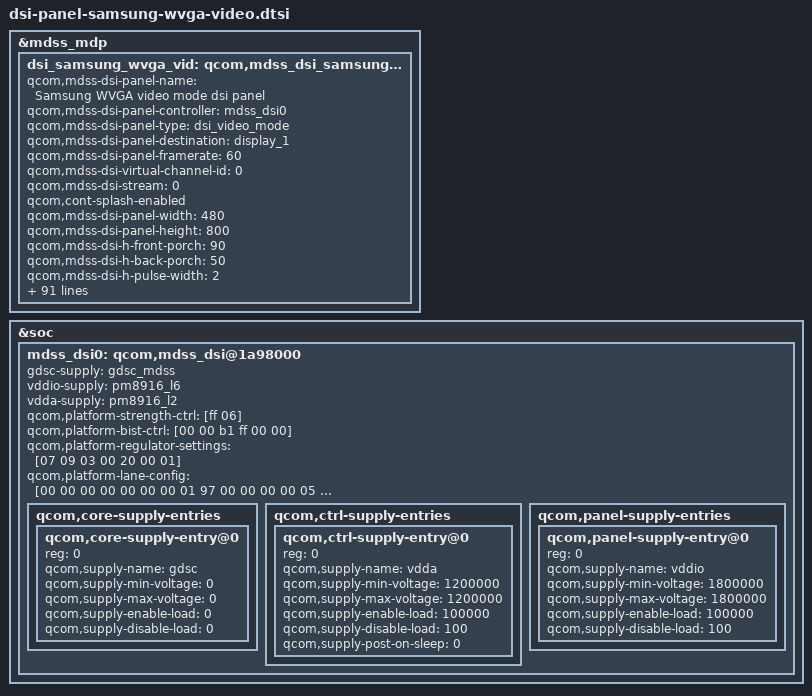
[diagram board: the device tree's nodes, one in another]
/* Copyright (c) 2013-2014, The Linux Foundation. All rights reserved.
 *
 * This program is free software; you can redistribute it and/or modify
 * it under the terms of the GNU General Public License version 2 and
 * only version 2 as published by the Free Software Foundation.
 *
 * This program is distributed in the hope that it will be useful,
 * but WITHOUT ANY WARRANTY; without even the implied warranty of
 * MERCHANTABILITY or FITNESS FOR A PARTICULAR PURPOSE.  See the
 * GNU General Public License for more details.
 */

/*---------------------------------------------------------------------------
 * This file is autogenerated file using gcdb parser. Please do not edit it.
 * Update input XML file to add a new entry or update variable in this file
 * VERSION = "1.0"
 *---------------------------------------------------------------------------

 */
&mdss_mdp {
	dsi_samsung_wvga_vid: qcom,mdss_dsi_samsung_wvga_video {
		qcom,mdss-dsi-panel-name = "Samsung WVGA video mode dsi panel";
		qcom,mdss-dsi-panel-controller = <&mdss_dsi0>;
		qcom,mdss-dsi-panel-type = "dsi_video_mode";
		qcom,mdss-dsi-panel-destination = "display_1";
		qcom,mdss-dsi-panel-framerate = <60>;
		qcom,mdss-dsi-virtual-channel-id = <0>;
		qcom,mdss-dsi-stream = <0>;
		qcom,cont-splash-enabled;
		qcom,mdss-dsi-panel-width = <480>;
		qcom,mdss-dsi-panel-height = <800>;
		qcom,mdss-dsi-h-front-porch = <90>;
		qcom,mdss-dsi-h-back-porch = <50>;
		qcom,mdss-dsi-h-pulse-width = <2>;
		qcom,mdss-dsi-h-sync-skew = <0>;
		qcom,mdss-dsi-v-back-porch = <2>;
		qcom,mdss-dsi-v-front-porch = <13>;
		qcom,mdss-dsi-v-pulse-width = <1>;
		qcom,mdss-dsi-h-left-border = <0>;
		qcom,mdss-dsi-h-right-border = <0>;
		qcom,mdss-dsi-v-top-border = <0>;
		qcom,mdss-dsi-v-bottom-border = <0>;
		qcom,mdss-dsi-bpp = <24>;
		qcom,mdss-dsi-underflow-color = <0xff>;
		qcom,mdss-dsi-border-color = <0>;
		qcom,mdss-dsi-on-command = [
			39 01 00 00 00 00 03 f0 5a 5a /* Tesk key ON */
			39 01 00 00 00 00 03 fc 5a 5a
			05 01 00 00 78 00 02 11 00 /* Sleep out  wait 120ms */

			/* Common setting - AVDD Setting */
			39 01 00 00 00 00 04 b8 38 0b 30

			/* Brightness condition set */
			39 01 00 00 00 00 22 /* Brightness gamma */
				ca 01 00 01 00 01 00 /* V255 RGB*/
				80 80 80 /* V203 RGB*/
				80 80 80 /* V151 RGB*/
				80 80 80 /* V87 RGB*/
				80 80 80 /* V51 RGB*/
				80 80 80 /* V35 RGB*/
				80 80 80 /* V23 RGB*/
				80 80 80 /* V11 RGB*/
				80 80 80 /* V3 RGB*/
				00 00 00 /* VT RGB*/

			39 01 00 00 00 00 06 b2 40 08 20 00 08 /* AID set */

			/* ELVSS Condition set */
			39 01 00 00 00 00 03 b6 28 0b /* ELVSS */

			/* ETC */
			39 01 00 00 00 00 02 55 00 /* ACL set */
			39 01 00 00 00 00 03 fc a5 a5
			05 01 00 00 00 00 02 29 00 /* Display on */];
		qcom,mdss-dsi-off-command = [05 01 00 00 23 00 02 28 00
				 05 01 00 00 78 00 02 10 00];
		qcom,mdss-dsi-gamma-update = [39 01 00 00 00 00 02 F7 03];
		qcom,mdss-dsi-on-command-state = "dsi_lp_mode";
		qcom,mdss-dsi-off-command-state = "dsi_hs_mode";
		qcom,mdss-dsi-h-sync-pulse = <0>;
		qcom,mdss-dsi-traffic-mode = "burst_mode";
		qcom,mdss-dsi-bllp-eof-power-mode;
		qcom,mdss-dsi-bllp-power-mode;
		qcom,mdss-dsi-lane-0-state;
		qcom,mdss-dsi-lane-1-state;
		qcom,mdss-dsi-panel-timings = [5E 16 0E 00 38 3C 12 1A 1C 03 04 00];
		qcom,mdss-dsi-t-clk-post = <0x04>;
		qcom,mdss-dsi-t-clk-pre = <0x17>;
		qcom,mdss-dsi-bl-min-level = <1>;
		qcom,mdss-dsi-bl-max-level = <255>;
		qcom,mdss-dsi-dma-trigger = "trigger_sw";
		qcom,mdss-dsi-mdp-trigger = "none";
		qcom,mdss-force-clk-lane-hs = <1>;
		qcom,mdss-dsi-bl-pmic-control-type = "bl_ctrl_dcs";
		qcom,mdss-dsi-reset-sequence = <1 5>, <0 1>, <1 10>;
		qcom,mdss-pan-physical-width-dimension = <56>;
		qcom,mdss-pan-physical-height-dimension = <94>;
		qcom,mdss-dsi-lp11-init;
		qcom,mdss-dsi-init-delay-us = <2000>;
		samsung,panel-manufacture-id-read-cmds = [
			06 01 00 00 00 00 01 DA 01 00
			06 01 00 00 00 00 01 DB 01 00
			06 01 00 00 00 00 01 DC 01 00
		];
		samsung,panel-acl-off-cmds = [39 01 00 00 72 00 02 55 00];
		/*
		the last byte in read commands  represent READ LENGH,
		like below  READ LENGH = 0x21
		*/

		samsung,panel-nv-mtp-read-cmds = [ 06 01 00 00 00 00 01 C8 21 00];
		samsung,panel-nv-mtp-read-hbm-cmds = [ 06 01 00 00 00 00 01 B5 07 0C];	/* read B5 13~19th , 12=0x0C*/
		samsung,panel-nv-mtp-read-hbm2-cmds = [ 06 01 00 00 00 00 01 B5 03 19];	/* read B5 26~28th , 25=0x19*/
		samsung,panel-nv-mtp-read-hbm3-cmds = [ 06 01 00 00 00 00 01 B6 11 00];	/* read B6 03~17th , 03=0x03*/
		samsung,panel-nv-mdnie-read-cmds = [ 06 01 00 00 00 00 01 B5 04 13];
		samsung,panel-test-key-enable-cmds = [ 39 00 00 00 00 00 03 F0 5A 5A];
		samsung,panel-test-key-disable-cmds = [ 39 01 00 00 00 00 03 F0 A5 A5];
		samsung,panel-nv-mdate-read-cmds = [ 06 01 00 00 00 00 01 B5 02 17];	/* read B6 24~25th , 23=0x17*/

		samsung,panel-nv-read-enable-cmds = [39 01 00 00 00 00 03 F0 5A 5A
						39 01 00 00 00 00 03 FC 5A 5A];
		samsung,panel-nv-read-disable-cmds = [39 01 00 00 00 00 03 FC A5 A5
						39 01 00 00 00 00 03 F0 A5 A5];
		samsung,panel-gamma-hbm-cmds-list = [39 00 00 00 00 00 22            /* Brightness Condition Set - Gamma 2.2 Setting*/
						ca 01 00 01 00 01 00 80
						80 80 80 80 80 80 80 80
						80 80 80 80 80 80 80 80
						80 80 80 80 80 80 80 00
						00 00
			];
		samsung,panel-etc-hbm-cmds = [
					39 00 00 00 00 00 06 B2 00 00 00 00 06	/* samsung_brightness_aor_condition */
					39 00 00 00 00 00 12 B6 28 0B 7C 7D 7C 7A 79 7A 7E 7E		/* C8h 40th - MPS / ELVSS setting */
						7E 7F 7E 7C 00 00 1A
					39 00 00 00 00 00 02 55 02		/* power saving Set */
					39 00 00 00 00 00 02 F7 03		/* Gamma, LTPS(AID) update */
			];
		samsung,panel-hbm-off-cmds = [
					39 00 00 00 00 00 12 B6 28 0B 7C 7D 7C 7A 79 7A 7E 7E		/* C8h 40th - MPS / ELVSS setting */
						7E 7F 7E 7C 00 00 1A
					39 01 00 00 00 00 02 F7 03		/* Gamma, LTPS(AID) update */
		];
		/*
		* ************************************************************************************************************************
		* AID command list and mappings
		* ************************************************************************************************************************
		*/
		samsung,panel-aid-cmds-list-350 = [
			39 00 00 00 00 00 06 B2 40 08 20 03 11 /* 0 samsung_brightness_aor_0p4 */
			39 00 00 00 00 00 06 B2 40 08 20 03 07 /* 1 samsung_brightness_aor_40p0 */
			39 00 00 00 00 00 06 B2 40 08 20 03 02 /* 2 samsung_brightness_aor_0p4 181*/
			39 00 00 00 00 00 06 B2 40 08 20 02 F7 /* 3 samsung_brightness_aor_0p4 179*/
			39 00 00 00 00 00 06 B2 40 08 20 02 F4 /* 4 samsung_brightness_aor_0p4 177*/
			39 00 00 00 00 00 06 B2 40 08 20 02 E8 /* 5 samsung_brightness_aor_0p4 175*/
			39 00 00 00 00 00 06 B2 40 08 20 02 E4 /* 6 samsung_brightness_aor_0p4 173*/
			39 00 00 00 00 00 06 B2 40 08 20 02 E2 /* 7 samsung_brightness_aor_0p4 110*/
			39 00 00 00 00 00 06 B2 40 08 20 02 D7 /* 8 samsung_brightness_aor_0p4 109*/
			39 00 00 00 00 00 06 B2 40 08 20 02 D2 /* 9 samsung_brightness_aor_0p4 108*/
			39 00 00 00 00 00 06 B2 40 08 20 02 C6 /* 10 samsung_brightness_aor_0p4 */
			39 00 00 00 00 00 06 B2 40 08 20 02 C4 /* 11 samsung_brightness_aor_0p4 108*/
			39 00 00 00 00 00 06 B2 40 08 20 02 B8 /* 12 samsung_brightness_aor_0p4 */
			39 00 00 00 00 00 06 B2 40 08 20 02 B3 /* 13 samsung_brightness_aor_0p4 */
			39 00 00 00 00 00 06 B2 40 08 20 02 A7 /* 14 samsung_brightness_aor_6p2 */
			39 00 00 00 00 00 06 B2 40 08 20 02 A2 /* 15 samsung_brightness_aor_81p6 */
			39 00 00 00 00 00 06 B2 40 08 20 02 96 /* 16 samsung_brightness_aor_80p6 */
			39 00 00 00 00 00 06 B2 40 08 20 02 89 /* 17 samsung_brightness_aor_79p0 */
			39 00 00 00 00 00 06 B2 40 08 20 02 84 /* 18 samsung_brightness_aor_77p9 */
			39 00 00 00 00 00 06 B2 40 08 20 02 76 /* 19 samsung_brightness_aor_75p8 */
			39 00 00 00 00 00 06 B2 40 08 20 02 67 /* 20samsung_brightness_aor_74p3 */
			39 00 00 00 00 00 06 B2 40 08 20 02 62 /* 21 samsung_brightness_aor_73p2 */
			39 00 00 00 00 00 06 B2 40 08 20 02 54 /* 22 samsung_brightness_aor_71p7 */
			39 00 00 00 00 00 06 B2 40 08 20 02 45 /* 23 samsung_brightness_aor_69p5 */
			39 00 00 00 00 00 06 B2 40 08 20 02 32 /* 24 samsung_brightness_aor_66p9 */
			39 00 00 00 00 00 06 B2 40 08 20 02 23 /* 25 samsung_brightness_aor_64p7 */
			39 00 00 00 00 00 06 B2 40 08 20 02 0C /* 26 samsung_brightness_aor_63p1 */
			39 00 00 00 00 00 06 B2 40 08 20 02 01 /* 27 samsung_brightness_aor_59p9 */
			39 00 00 00 00 00 06 B2 40 08 20 01 E7 /* 28 samsung_brightness_aor_57p3 */
			39 00 00 00 00 00 06 B2 40 08 20 01 D4 /* 29 samsung_brightness_aor_54p6 */
			39 00 00 00 00 00 06 B2 40 08 20 01 BD /* 30 samsung_brightness_aor_51p9 */
			39 00 00 00 00 00 06 B2 40 08 20 02 A6 /* 31 samsung_brightness_aor_48p6 */
			39 00 00 00 00 00 06 B2 40 08 20 01 87 /* 32 samsung_brightness_aor_44p8 */
			39 00 00 00 00 00 06 B2 40 08 20 01 71 /* 33 samsung_brightness_aor_41p0 */
			39 00 00 00 00 00 06 B2 40 08 20 01 49 /* 34 samsung_brightness_aor_37p2 */
			39 00 00 00 00 00 06 B2 40 08 20 01 34 /* 35 samsung_brightness_aor_32p7 */
			39 00 00 00 00 00 06 B2 40 08 20 01 13 /* 36 samsung_brightness_aor_27p7 */
			39 00 00 00 00 00 06 B2 40 08 20 00 E8 /* 37 samsung_brightness_aor_22p8 */
			39 00 00 00 00 00 06 B2 40 08 20 00 C3 /* 38 samsung_brightness_aor_17p7 */
			39 00 00 00 00 00 06 B2 40 08 20 00 97 /* 39 samsung_brightness_aor_11p6 */
			39 00 00 00 00 00 06 B2 40 08 20 00 66 /* 40 samsung_brightness_aor_6p6 */
			39 00 00 00 00 00 06 B2 40 08 20 00 37 /* 41 samsung_brightness_aor_0p5 */
			39 00 00 00 00 00 06 B2 40 08 20 00 08 /* 42 samsung_brightness_aor_40p0 */
			];

		samsung,panel-aid-map-table-350 = <
			5    0         6   1        7    2       8    3      9    4
			10   5         11   6       12   7       13   8     14   9
			15   10        16   11       17   12       19   13     20   14
			21   15        22   16       24   17       25   18     27   19
			29   20        30   21       32   22       34   23     37   24
			39   25        41   26       44   27       47   28     50   29
			53   30        56   31       60   32       64   33     68   34
			72   35        77   35       82   35       87   35     93   35
			98   35        105  35       111  35       119  35     126  35
			134  35        143  35       152  35       162  35     172  36
			183  37        195  38       207  39       220  40     234  41
			249  42        265  42       282  42       300  42     316  42
			333  42        350  42
		>;

		/*
		* ************************************************************************************************************************
		* ACL command list and mappings
		* ************************************************************************************************************************
		*/
		samsung,panel-acl-cmds-list = [
			39 00 00 00 00 00 02 55 00
			39 00 00 00 00 00 02 55 01
			39 00 00 00 00 00 02 55 02
			39 00 00 00 00 00 02 55 03
		];

		samsung,panel-acl-map-table =  <
			5    2         6    2        7    2         8    2      9    2
			10   2         11   2        12   2         13   2      14   2
			15   2         16   2        17   2         19   2      20   2
			21   2         22   2        24   2         25   2      27   2
			29   2         30   2        32   2         34   2      37   2
			39   2         41   2        44   2         47   2      50   2
			53   2         56   2        60   2         64   2      68   2
			72   2         77   2        82   2         87   2      93   2
			98   2         105  2        111  2         119  2      126  2
			134  2         143  2        152  2         162  2      172  2
			183  2         195  2        207  2         220  2      234  2
			249  2         265  2        282  2         300  2      316  2
			333  2         350  2
		>;
		/*
		* ************************************************************************************************************************
		* ELVSS(ACL Off) command list and mappings
		* ************************************************************************************************************************
		*/
		samsung,panel-elvss-cmds-list-350 = [
			39 00 00 00 00 00 03 B6 28 13 /* 0 DEFAULT_ELVSS(0x16) */
			39 00 00 00 00 00 03 B6 28 12 /* 1 DEFAULT_ELVSS(0x15) */
			39 00 00 00 00 00 03 B6 28 11 /* 2 DEFAULT_ELVSS(0x14) */
			39 00 00 00 00 00 03 B6 28 10 /* 3 DEFAULT_ELVSS(0x13) */
			39 00 00 00 00 00 03 B6 28 0F /* 4 DEFAULT_ELVSS(0x12) */
			39 00 00 00 00 00 03 B6 28 0E /* 5 DEFAULT_ELVSS(0x11) */
			39 00 00 00 00 00 03 B6 28 0D /* 6 DEFAULT_ELVSS(0x10) */
			39 00 00 00 00 00 03 B6 28 0C /* 7 DEFAULT_ELVSS(0x0F) */
			39 00 00 00 00 00 03 B6 28 0B /* 8 DEFAULT_ELVSS(0x0E) */
		];
		/* bl_level, Index in elvss command list */
		samsung,panel-elvss-map-table-350 = <
			5    0         6    0        7    0         8    0      9    0
			10   0         11   0        12   0         13   0      14   0
			15   0         16   0        17   0         19   0      20   0
			21   0         22   0        24   0         25   0      27   0
			29   0         30   0        32   0         34   0      37   0
			39   0         41   0        44   0         47   0      50   0
			53   0         56   0        60   0         64   0      68   0
			72   0         77   0        82   0         87   0      93   0
			98   0         105  0        111  0         119  1      126  1
			134  2         143  2        152  3         162  3      172  3
			183  3        195  3       207  4        220  4     234  4
			249  4        265  5       282  5        300   6     316  7
			333  7        350  8
			>;
		samsung,panel-smart-acl-elvss-cmds-list = [
			39 00 00 00 00 00 03 B6 28 15 /* 0 DEFAULT_ELVSS(0x16) */
			39 00 00 00 00 00 03 B6 28 14 /* 1 DEFAULT_ELVSS(0x15) */
			39 00 00 00 00 00 03 B6 28 13 /* 2 DEFAULT_ELVSS(0x14) */
			39 00 00 00 00 00 03 B6 28 12 /* 3 DEFAULT_ELVSS(0x13) */
			39 00 00 00 00 00 03 B6 28 11 /* 4 DEFAULT_ELVSS(0x12) */
			39 00 00 00 00 00 03 B6 28 10 /* 5 DEFAULT_ELVSS(0x11) */
			39 00 00 00 00 00 03 B6 28 0F /* 6 DEFAULT_ELVSS(0x10) */
			39 00 00 00 00 00 03 B6 28 0E /* 7 DEFAULT_ELVSS(0x0F) */
			39 00 00 00 00 00 03 B6 28 0D /* 8 DEFAULT_ELVSS(0x0E) */
		];

			/* bl_level, Index in elvss command list */
		samsung,panel-smart-acl-elvss-map-table = <
			5    0         6    0        7    0         8    0      9    0
			10   0         11   0        12   0         13   0      14   0
			15   0         16   0        17   0         19   0      20   0
			21   0         22   0        24   0         25   0      27   0
			29   0         30   0        32   0         34   0      37   0
			39   0         41   0        44   0         47   0      50   0
			53   0         56   0        60   0         64   0      68   0
			72   0         77   0        82   0         87   0      93   0
			98   0         105  0        111  0         119  1      126  1
			134  2         143  2        152  3         162  3      172  3
			183  3        195  3       207  4        220  4     234  4
			249  4        265  5       282  5        300   6     316  7
			333  7        350  8
			>;
		/*
		* ************************************************************************************************************************
		* candela to index mappings
		* ************************************************************************************************************************
		*/
		samsung,panel-candella-mapping-table-350 = <
		/*<idx>	  <from>  <till> <candella> */
				0		0		5		5
				1		6		6		6
				2		7		7		7
				3		8		8		8
				4		9		9		9
				5		10		10		10
				6		11		11		11
				7		12		12		12
				8		13		13		13
				9		14		14		14
				10		15		15		15
				11		16		16		16
				12		17		18		17
				13		19		19		19
				14		20		20		20
				15		21		21		21
				16		22		23		22
				17		24		25		24
				18		26		27		25
				19		28		29		27
				20		30		31		29
				21		32		33		30
				22		33		34		32
				23		35		36		34
				24		37		38		37
				25		39		40		39
				26		41		43		41
				27		44		46		44
				28		47		49		47
				29		50		52		50
				30		39		40		53
				31		41		43		56
				32		44		46		60
				33		47		49		64
				34		50		52		68
				35		53		56		72
				36		57		59		77
				37		60		63		82
				38		64		67		87
				39		68		71		93
				40		71		76		98
				41		77		80		105
				42		81		86		111
				43		87		91		119
				44		92		97		126
				45		98		104		134
				46		105		110		143
				47		111		118		152
				48		119		125		162
				49		126		133		172
				50		134		142		183
				51		143		150		195
				52		151		160		207
				53		161		170		220
				54		171		181		234
				55		182		193		249
				56		194		205		265
				57		206		218		282
				58		219		230		300
				59		231		242		316
				60		243		254		333
				61		255		255		350
		>;
		samsung,panel-gamma-cmds-list = [
			39 00 00 00 00 00 22 CA 01		/* Brightness Condition Set - Gamma 2.2 Setting*/
			00 01 00 01 00 80 80 80
			80 80 80 80 80 80 80 80
			80 80 80 80 80 80 80 80
			80 80 80 80 80 00 00 00
			39 00 00 00 00 00 02 F7 03

		];
	};
};
&soc {
	mdss_dsi0: qcom,mdss_dsi@1a98000 {
		gdsc-supply = <&gdsc_mdss>;
		vddio-supply = <&pm8916_l6>;
		vdda-supply = <&pm8916_l2>;
		qcom,platform-strength-ctrl = [ff 06];
		qcom,platform-bist-ctrl = [00 00 b1 ff 00 00];
		qcom,platform-regulator-settings = [07 09 03 00 20 00 01];
		qcom,platform-lane-config = [00 00 00 00 00 00 00 01 97
			00 00 00 00 05 00 00 01 97
			00 00 00 00 0a 00 00 01 97
			00 00 00 00 0f 00 00 01 97
			00 c0 00 00 00 00 00 01 bb];
		qcom,core-supply-entries {
			#address-cells = <1>;
			#size-cells = <0>;

			qcom,core-supply-entry@0 {
				reg = <0>;
				qcom,supply-name = "gdsc";
				qcom,supply-min-voltage = <0>;
				qcom,supply-max-voltage = <0>;
				qcom,supply-enable-load = <0>;
				qcom,supply-disable-load = <0>;
			};
		};
		qcom,ctrl-supply-entries {
			#address-cells = <1>;
			#size-cells = <0>;

			qcom,ctrl-supply-entry@0 {
				reg = <0>;
				qcom,supply-name = "vdda";
				qcom,supply-min-voltage = <1200000>;
				qcom,supply-max-voltage = <1200000>;
				qcom,supply-enable-load = <100000>;
				qcom,supply-disable-load = <100>;
				qcom,supply-post-on-sleep = <0>;
			};
		};
		qcom,panel-supply-entries {
			#address-cells = <1>;
			#size-cells = <0>;

			qcom,panel-supply-entry@0 {
				reg = <0>;
				qcom,supply-name = "vddio";
				qcom,supply-min-voltage = <1800000>;
				qcom,supply-max-voltage = <1800000>;
				qcom,supply-enable-load = <100000>;
				qcom,supply-disable-load = <100>;
			};
		};
	};
};
